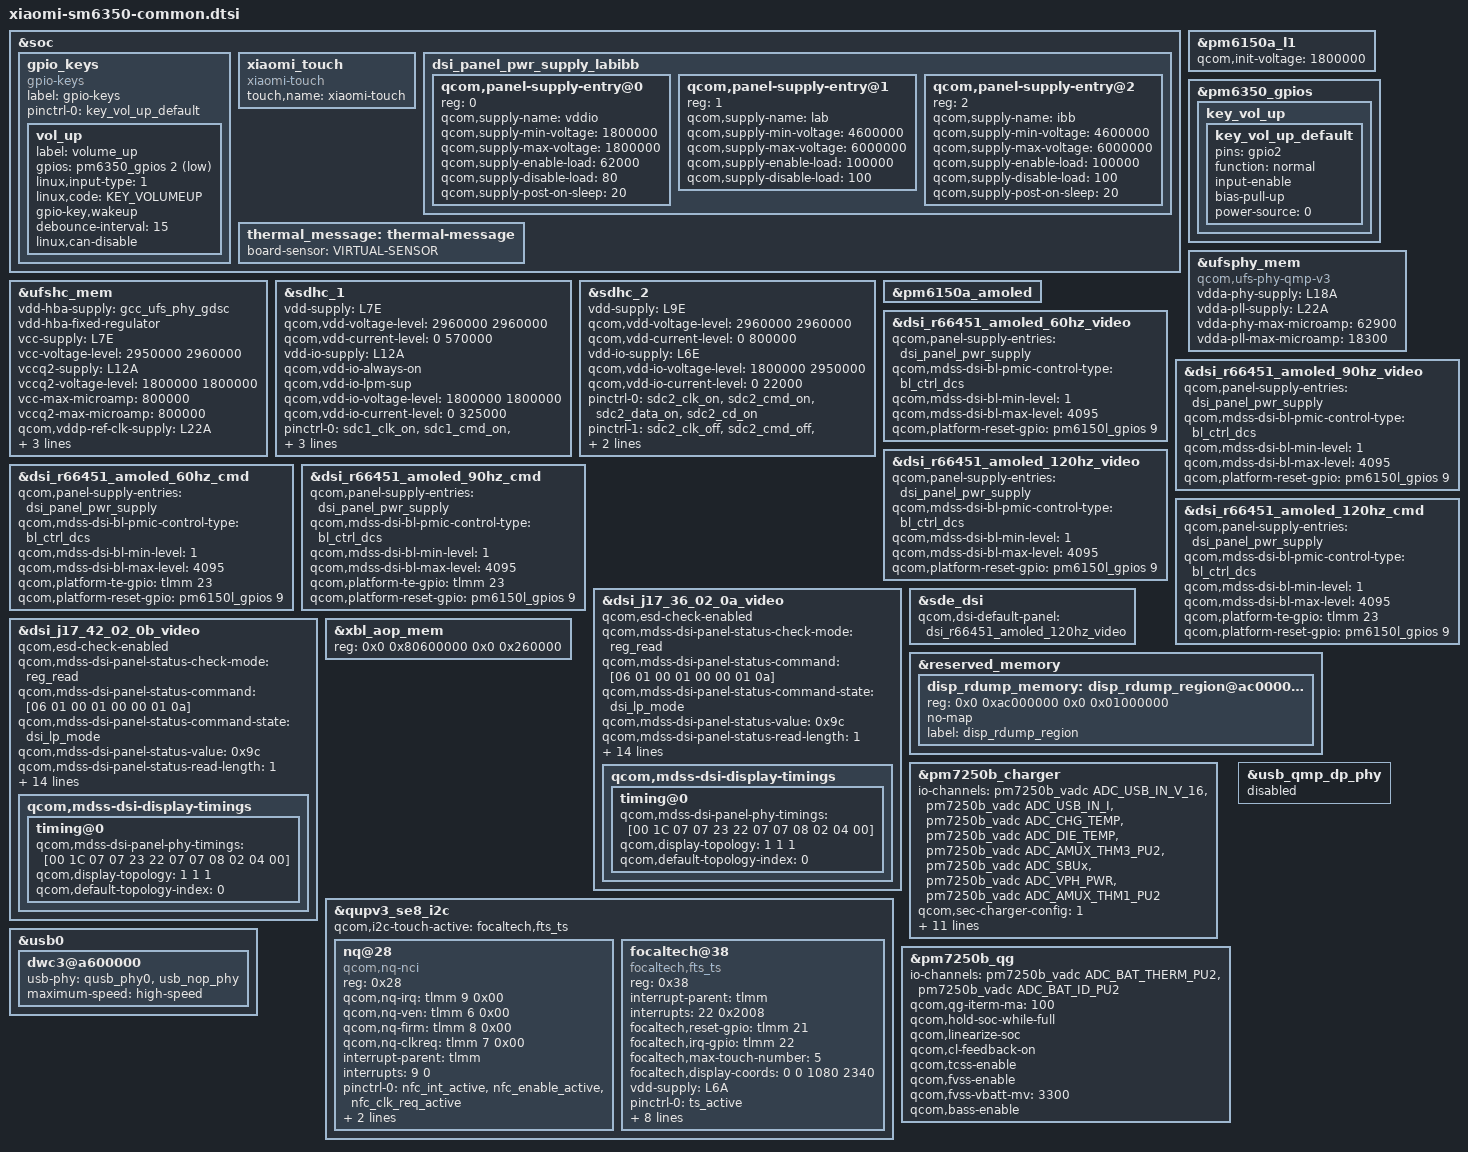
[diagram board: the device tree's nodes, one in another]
#include <dt-bindings/gpio/gpio.h>
#include <dt-bindings/input/linux-event-codes.h>
#include <dt-bindings/iio/qcom,spmi-vadc.h>
#include "lagoon-thermal-overlay.dtsi"
#include "lagoon-sde-display.dtsi"
#include "camera/gauguin-camera-sensor-mtp.dtsi"
#include "dsi-panel-j17-36-02-0a-dsc-video.dtsi"
#include "dsi-panel-j17-42-02-0b-dsc-video.dtsi"

&soc {
	gpio_keys {
		compatible = "gpio-keys";
		label = "gpio-keys";

		pinctrl-names = "default";
		pinctrl-0 = <&key_vol_up_default>;

		vol_up {
			label = "volume_up";
			gpios = <&pm6350_gpios 2 GPIO_ACTIVE_LOW>;
			linux,input-type = <1>;
			linux,code = <KEY_VOLUMEUP>;
			gpio-key,wakeup;
			debounce-interval = <15>;
			linux,can-disable;
		};
	};

	xiaomi_touch {
		compatible = "xiaomi-touch";
		status = "ok";
		touch,name = "xiaomi-touch";
	};

	dsi_panel_pwr_supply_labibb: dsi_panel_pwr_supply_labibb {
		#address-cells = <1>;
		#size-cells = <0>;

		qcom,panel-supply-entry@0 {
			reg = <0>;
			qcom,supply-name = "vddio";
			qcom,supply-min-voltage = <1800000>;
			qcom,supply-max-voltage = <1800000>;
			qcom,supply-enable-load = <62000>;
			qcom,supply-disable-load = <80>;
			qcom,supply-post-on-sleep = <20>;
		};

		qcom,panel-supply-entry@1 {
			reg = <1>;
			qcom,supply-name = "lab";
			qcom,supply-min-voltage = <4600000>;
			qcom,supply-max-voltage = <6000000>;
			qcom,supply-enable-load = <100000>;
			qcom,supply-disable-load = <100>;
		};

		qcom,panel-supply-entry@2 {
			reg = <2>;
			qcom,supply-name = "ibb";
			qcom,supply-min-voltage = <4600000>;
			qcom,supply-max-voltage = <6000000>;
			qcom,supply-enable-load = <100000>;
			qcom,supply-disable-load = <100>;
			qcom,supply-post-on-sleep = <20>;
		};
	};

	thermal_message: thermal-message {
		board-sensor = "VIRTUAL-SENSOR";
	};

};

&pm6150a_l1 {
	qcom,init-voltage = <1800000>;
};

&pm6350_gpios {
	key_vol_up {
		key_vol_up_default: key_vol_up_default {
			pins = "gpio2";
			function = "normal";
			input-enable;
			bias-pull-up;
			power-source = <0>;
		};
	};
};

&ufsphy_mem {
	compatible = "qcom,ufs-phy-qmp-v3";

	vdda-phy-supply = <&L18A>;
	vdda-pll-supply = <&L22A>;
	vdda-phy-max-microamp = <62900>;
	vdda-pll-max-microamp = <18300>;

	status = "ok";
};

&ufshc_mem {
	vdd-hba-supply = <&gcc_ufs_phy_gdsc>;
	vdd-hba-fixed-regulator;
	vcc-supply = <&L7E>;
	vcc-voltage-level = <2950000 2960000>;
	vccq2-supply = <&L12A>;
	vccq2-voltage-level = <1800000 1800000>;
	vcc-max-microamp = <800000>;
	vccq2-max-microamp = <800000>;

	qcom,vddp-ref-clk-supply = <&L22A>;
	qcom,vddp-ref-clk-max-microamp = <100>;
	qcom,vddp-ref-clk-min-uV = <1152000>;
	qcom,vddp-ref-clk-max-uV = <1200000>;
	status = "ok";
};

&sdhc_1 {
	vdd-supply = <&L7E>;
	qcom,vdd-voltage-level = <2960000 2960000>;
	qcom,vdd-current-level = <0 570000>;

	vdd-io-supply = <&L12A>;
	qcom,vdd-io-always-on;
	qcom,vdd-io-lpm-sup;
	qcom,vdd-io-voltage-level = <1800000 1800000>;
	qcom,vdd-io-current-level = <0 325000>;

	pinctrl-names = "active", "sleep";
	pinctrl-0 = <&sdc1_clk_on &sdc1_cmd_on &sdc1_data_on
					&sdc1_rclk_on>;
	pinctrl-1 = <&sdc1_clk_off &sdc1_cmd_off &sdc1_data_off
					&sdc1_rclk_off>;

	status = "ok";
};

&sdhc_2 {
	vdd-supply = <&L9E>;
	qcom,vdd-voltage-level = <2960000 2960000>;
	qcom,vdd-current-level = <0 800000>;

	vdd-io-supply = <&L6E>;
	qcom,vdd-io-voltage-level = <1800000 2950000>;
	qcom,vdd-io-current-level = <0 22000>;

	pinctrl-names = "active", "sleep";
	pinctrl-0 = <&sdc2_clk_on  &sdc2_cmd_on &sdc2_data_on &sdc2_cd_on>;
	pinctrl-1 = <&sdc2_clk_off &sdc2_cmd_off &sdc2_data_off &sdc2_cd_off>;

	cd-gpios = <&tlmm 94 GPIO_ACTIVE_HIGH>;

	status = "ok";
};

&pm6150a_amoled {
	status = "ok";
};

&dsi_r66451_amoled_60hz_video {
	qcom,panel-supply-entries = <&dsi_panel_pwr_supply>;
	qcom,mdss-dsi-bl-pmic-control-type = "bl_ctrl_dcs";
	qcom,mdss-dsi-bl-min-level = <1>;
	qcom,mdss-dsi-bl-max-level = <255>;
	qcom,mdss-dsi-bl-max-level = <4095>;
	qcom,platform-reset-gpio = <&pm6150l_gpios 9 0>;
};

&dsi_r66451_amoled_90hz_video {
	qcom,panel-supply-entries = <&dsi_panel_pwr_supply>;
	qcom,mdss-dsi-bl-pmic-control-type = "bl_ctrl_dcs";
	qcom,mdss-dsi-bl-min-level = <1>;
	qcom,mdss-dsi-bl-max-level = <255>;
	qcom,mdss-dsi-bl-max-level = <4095>;
	qcom,platform-reset-gpio = <&pm6150l_gpios 9 0>;
};

&dsi_r66451_amoled_120hz_video {
	qcom,panel-supply-entries = <&dsi_panel_pwr_supply>;
	qcom,mdss-dsi-bl-pmic-control-type = "bl_ctrl_dcs";
	qcom,mdss-dsi-bl-min-level = <1>;
	qcom,mdss-dsi-bl-max-level = <255>;
	qcom,mdss-dsi-bl-max-level = <4095>;
	qcom,platform-reset-gpio = <&pm6150l_gpios 9 0>;
};

&dsi_r66451_amoled_60hz_cmd {
	qcom,panel-supply-entries = <&dsi_panel_pwr_supply>;
	qcom,mdss-dsi-bl-pmic-control-type = "bl_ctrl_dcs";
	qcom,mdss-dsi-bl-min-level = <1>;
	qcom,mdss-dsi-bl-max-level = <255>;
	qcom,mdss-dsi-bl-max-level = <4095>;
	qcom,platform-te-gpio = <&tlmm 23 0>;
	qcom,platform-reset-gpio = <&pm6150l_gpios 9 0>;
};

&dsi_r66451_amoled_90hz_cmd {
	qcom,panel-supply-entries = <&dsi_panel_pwr_supply>;
	qcom,mdss-dsi-bl-pmic-control-type = "bl_ctrl_dcs";
	qcom,mdss-dsi-bl-min-level = <1>;
	qcom,mdss-dsi-bl-max-level = <255>;
	qcom,mdss-dsi-bl-max-level = <4095>;
	qcom,platform-te-gpio = <&tlmm 23 0>;
	qcom,platform-reset-gpio = <&pm6150l_gpios 9 0>;
};

&dsi_r66451_amoled_120hz_cmd {
	qcom,panel-supply-entries = <&dsi_panel_pwr_supply>;
	qcom,mdss-dsi-bl-pmic-control-type = "bl_ctrl_dcs";
	qcom,mdss-dsi-bl-min-level = <1>;
	qcom,mdss-dsi-bl-max-level = <255>;
	qcom,mdss-dsi-bl-max-level = <4095>;
	qcom,platform-te-gpio = <&tlmm 23 0>;
	qcom,platform-reset-gpio = <&pm6150l_gpios 9 0>;
};

&dsi_j17_36_02_0a_video {
	qcom,esd-check-enabled;
	qcom,mdss-dsi-panel-status-check-mode = "reg_read";
	qcom,mdss-dsi-panel-status-command = [06 01 00 01 00 00 01 0a];
	qcom,mdss-dsi-panel-status-command-state = "dsi_lp_mode";
	qcom,mdss-dsi-panel-status-value = <0x9c>;
	qcom,mdss-dsi-panel-status-read-length = <1>;
	qcom,panel-supply-entries = <&dsi_panel_pwr_supply_labibb>;
	qcom,mdss-dsi-bl-pmic-control-type = "bl_ctrl_wled";
	qcom,platform-te-gpio = <&tlmm 23 0>;
	qcom,platform-reset-gpio = <&pm6150l_gpios 9 0>;

	qcom,dsi-ctrl-num = <0>;
	qcom,dsi-phy-num = <0>;
	qcom,dsi-select-clocks = "mux_byte_clk0", "mux_pixel_clk0",
		"src_byte_clk0", "src_pixel_clk0",
		"shadow_byte_clk0", "shadow_pixel_clk0";

	qcom,mdss-dsi-t-clk-post = <0x0D>;
	qcom,mdss-dsi-t-clk-pre = <0x2F>;
	qcom,mdss-dsi-display-timings {
		timing@0 {
			qcom,mdss-dsi-panel-phy-timings = [00 1C 07 07 23 22 07
				07 08 02 04 00];
			qcom,display-topology = <1 1 1>;
			qcom,default-topology-index = <0>;
		};
	};
};

&dsi_j17_42_02_0b_video {
	qcom,esd-check-enabled;
	qcom,mdss-dsi-panel-status-check-mode = "reg_read";
	qcom,mdss-dsi-panel-status-command = [06 01 00 01 00 00 01 0a];
	qcom,mdss-dsi-panel-status-command-state = "dsi_lp_mode";
	qcom,mdss-dsi-panel-status-value = <0x9c>;
	qcom,mdss-dsi-panel-status-read-length = <1>;
	qcom,panel-supply-entries = <&dsi_panel_pwr_supply_labibb>;
	qcom,mdss-dsi-bl-pmic-control-type = "bl_ctrl_wled";
	qcom,platform-te-gpio = <&tlmm 23 0>;
	qcom,platform-reset-gpio = <&pm6150l_gpios 9 0>;

	qcom,dsi-ctrl-num = <0>;
	qcom,dsi-phy-num = <0>;
	qcom,dsi-select-clocks = "mux_byte_clk0", "mux_pixel_clk0",
		"src_byte_clk0", "src_pixel_clk0",
		"shadow_byte_clk0", "shadow_pixel_clk0";

	qcom,mdss-dsi-t-clk-post = <0x0D>;
	qcom,mdss-dsi-t-clk-pre = <0x2F>;
	qcom,mdss-dsi-display-timings {
		timing@0 {
			qcom,mdss-dsi-panel-phy-timings = [00 1C 07 07 23 22 07
				07 08 02 04 00];
			qcom,display-topology = <1 1 1>;
			qcom,default-topology-index = <0>;
		};
	};
};

&sde_dsi {
	qcom,dsi-default-panel = <&dsi_r66451_amoled_120hz_video>;
};

&xbl_aop_mem {
	reg = <0x0 0x80600000 0x0 0x260000>;
};

&reserved_memory {
	disp_rdump_memory: disp_rdump_region@ac000000 {
		reg = <0x0 0xac000000 0x0 0x01000000>;
		no-map;
		label = "disp_rdump_region";
	};
};

&qupv3_se8_i2c {
	status = "ok";
	#address-cells = <1>;
	#size-cells = <0>;
	nq@28 {
		compatible = "qcom,nq-nci";
		reg = <0x28>;
		qcom,nq-irq = <&tlmm 9 0x00>;
		qcom,nq-ven = <&tlmm 6 0x00>;
		qcom,nq-firm = <&tlmm 8 0x00>;
		qcom,nq-clkreq = <&tlmm 7 0x00>;
		interrupt-parent = <&tlmm>;
		interrupts = <9 0>;
		interrupt-names = "nfc_irq";
		pinctrl-names = "nfc_active", "nfc_suspend";
		pinctrl-0 = <&nfc_int_active &nfc_enable_active
				&nfc_clk_req_active>;
		pinctrl-1 = <&nfc_int_suspend &nfc_enable_suspend
				&nfc_clk_req_suspend>;
	};
};

&pm7250b_charger {
	status = "ok";
	io-channels = <&pm7250b_vadc ADC_USB_IN_V_16>,
		      <&pm7250b_vadc ADC_USB_IN_I>,
		      <&pm7250b_vadc ADC_CHG_TEMP>,
		      <&pm7250b_vadc ADC_DIE_TEMP>,
		      <&pm7250b_vadc ADC_AMUX_THM3_PU2>,
		      <&pm7250b_vadc ADC_SBUx>,
		      <&pm7250b_vadc ADC_VPH_PWR>,
		      <&pm7250b_vadc ADC_AMUX_THM1_PU2>;
	io-channel-names = "usb_in_voltage",
			   "usb_in_current",
			   "chg_temp",
			   "die_temp",
			   "conn_temp",
			   "sbux_res",
			   "vph_voltage",
			   "skin_temp";
	qcom,sec-charger-config = <1>;
	qcom,auto-recharge-soc = <98>;
	//qcom,step-charging-enable;
	//qcom,sw-jeita-enable;
	qcom,charger-temp-max = <800>;
	qcom,smb-temp-max = <800>;
	qcom,suspend-input-on-debug-batt;
	qcom,fcc-stepping-enable;
	qcom,fcc-step-delay-ms = <100>;
	qcom,fcc-step-size-ua = <100000>;
	qcom,smb-internal-pull-kohm = <0>;
	qcom,en-skin-therm-mitigation;
	qcom,thermal-mitigation = <6000000 6000000 6000000 6000000 6000000
				5000000 4500000 4000000 3500000 3000000 2500000
				2000000 1500000 1000000 500000>;
};

&pm7250b_qg {
	status = "ok";
	io-channels = <&pm7250b_vadc ADC_BAT_THERM_PU2>,
		      <&pm7250b_vadc ADC_BAT_ID_PU2>;
	io-channel-names = "batt-therm",
			   "batt-id";
	qcom,qg-iterm-ma = <100>;
	qcom,hold-soc-while-full;
	qcom,linearize-soc;
	qcom,cl-feedback-on;
	qcom,tcss-enable;
	qcom,fvss-enable;
	qcom,fvss-vbatt-mv = <3300>;
	qcom,bass-enable;
};

&usb_qmp_dp_phy {
	status = "disabled";
};

&usb0 {
	dwc3@a600000 {
		usb-phy = <&qusb_phy0>, <&usb_nop_phy>;
		maximum-speed = "high-speed";
	};
};

&qupv3_se8_i2c {
	#address-cells = <1>;
	#size-cells = <0>;

	status = "ok";
	qcom,i2c-touch-active = "focaltech,fts_ts";

	focaltech@38 {
		compatible = "focaltech,fts_ts";
		reg = <0x38>;
		interrupt-parent = <&tlmm>;
		interrupts = <22 0x2008>;
		focaltech,reset-gpio = <&tlmm 21 0x00>;
		focaltech,irq-gpio = <&tlmm 22 0x2008>;
		focaltech,max-touch-number = <5>;
		focaltech,display-coords = <0 0 1080 2340>;

		vdd-supply = <&L6A>;

		pinctrl-names = "pmx_ts_active", "pmx_ts_suspend","pmx_ts_release";
		pinctrl-0 = <&ts_active>;
		pinctrl-1 = <&ts_int_suspend &ts_reset_suspend>;
		pinctrl-2 = <&pmx_ts_release>;

		panel = <&dsi_r66451_amoled_60hz_cmd
			 &dsi_r66451_amoled_90hz_cmd
			 &dsi_r66451_amoled_120hz_cmd
			 &dsi_r66451_amoled_60hz_video
			 &dsi_r66451_amoled_90hz_video
			 &dsi_r66451_amoled_120hz_video>;
	};
};

